# STM32MP25_CM33 register map
File version: 1.3
CPU: CM33 r0p1, little endian, MPU, FPU, vendor SysTick, 8 interrupt priority bits
Registers are 32-bit, read-write, reset 0x0 unless marked. A register's access mark holds for its fields unless they carry their own. Offsets are from the block's base; [hi:lo] are bit positions.

## PKA — PKA register blank and RAM
Base 0x42060000
Same registers: PKA_S 0x52060000
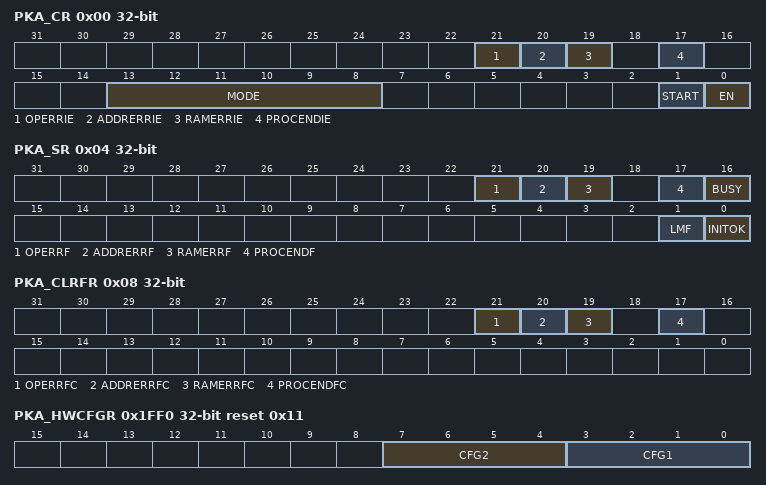
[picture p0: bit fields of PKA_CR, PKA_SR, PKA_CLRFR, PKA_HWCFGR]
0x00 PKA_CR — PKA control register
  [21] OPERRIE — Operation error interrupt enable
    0=No interrupt is generated when OPERRF flag is set in PKA_SR; 1=An interrupt is generated when OPERRF flag is set in PKA_SR
  [20] ADDRERRIE — Address error interrupt enable
    0=No interrupt is generated when ADDRERRF flag is set in PKA_SR; 1=An interrupt is generated when ADDRERRF flag is set in PKA_SR
  [19] RAMERRIE — RAM error interrupt enable
    0=No interrupt is generated when RAMERRF flag is set in PKA_SR; 1=An interrupt is generated when RAMERRF flag is set in PKA_SR
  [17] PROCENDIE — End of operation interrupt enable
    0=No interrupt is generated when PROCENDF flag is set in PKA_SR; 1=An interrupt is generated when PROCENDF flag is set in PKA_SR
  [13:8] MODE — PKA operation code When an operation not listed here is written by the application with EN bit set, OPERRF bit is set in PKA_SR register, and the write to MODE bit field is ignored. When PKA is configured in limited mode (LMF = 1 in PKA_SR), writing a MODE different from 0x26 with EN bit to 1 triggers OPERRF bit to be set and write to MODE bit is ignored.
    0=Montgomery parameter computation then modular exponentiation; 1=Montgomery parameter computation only; 2=Modular exponentiation only (Montgomery parameter must be loaded first); 3=Modular exponentiation (protected, used when manipulating secrets); 32=Montgomery parameter computation then ECC scalar multiplication (protected); 36=ECDSA sign (protected); 38=ECDSA verification; 40=Point on elliptic curve Fp check; 7=RSA CRT exponentiation; 8=Modular inversion; 9=Arithmetic addition; 10=Arithmetic subtraction; 11=Arithmetic multiplication; 12=Arithmetic comparison; 13=Modular reduction; 14=Modular addition; 15=Modular subtraction; 16=Montgomery multiplication; 35=ECC complete addition; 39=ECC double base ladder; 47=ECC projective to affine
  [1] START — start the operation Writing 1 to this bit starts the operation which is selected by MODE[5:0], using the operands and data already written to the PKA RAM. This bit is always read as 0. When an illegal operation is selected while START bit is set no operation is started, and OPERRF bit is set in PKA_SR. Note: START is ignored if PKA is busy.
  [0] EN — PKA enable When an illegal operation is selected while EN = 1, OPERRF bit is set in PKA_SR. See PKA_CR.MODE bit field for details. Note: When EN = 0, PKA RAM can still be accessed by the application.
    0=Disable PKA; 1=Enable PKA. PKA becomes functional when INITOK is set by hardware in PKA_SR.
0x04 PKA_SR ro — PKA status register
  [21] OPERRF — Operation error flag This bit is cleared using OPERRFC bit in PKA_CLRFR.
    0=No event error; 1=An illegal or unknown operation has been selected in PKA_CR register
  [20] ADDRERRF — Address error flag This bit is cleared using ADDRERRFC bit in PKA_CLRFR.
    0=No address error; 1=Address access is out of range (unmapped address)
  [19] RAMERRF — PKA RAM error flag This bit is cleared using RAMERRFC bit in PKA_CLRFR.
    0=No PKA RAM access error; 1=An AHB access to the PKA RAM occurred while the PKA core was computing and using its internal RAM (AHB PKA_RAM access are not allowed while PKA operation is in progress)
  [17] PROCENDF — PKA end of operation flag
    0=Operation in progress; 1=PKA operation is completed. This flag is set when the BUSY bit is deasserted.
  [16] BUSY — Busy flag This bit is set whenever a PKA operation is in progress (START = 1 in PKA_CR). It is automatically cleared when the computation is complete, making PKA RAM accessible again. If PKA is started with a wrong opcode, it stays busy for a couple of cycles, then it aborts automatically the operation and goes back to ready (BUSY = 0).
    0=No operation is in progress (default); 1=An operation is in progress
  [1] LMF — Limited mode flag This bit is updated when EN bit in PKA_CR is set
    0=All values documented in MODE bit field can be used; 1=Only ECDSA verification (MODE = 0x26) is supported by the PKA
  [0] INITOK — PKA initialization OK This bit is asserted when PKA initialization is complete. When RNG is not able to output proper random numbers INITOK stays at 0.
    0=PKA is not initialized correctly. START bit cannot be set.; 1=PKA is initialized correctly and can be used normally
0x08 PKA_CLRFR wo — PKA clear flag register
  [21] OPERRFC — Clear operation error flag
    0=No action; 1=Clear the OPERRF flag in PKA_SR
  [20] ADDRERRFC — Clear address error flag
    0=No action; 1=Clear the ADDRERRF flag in PKA_SR
  [19] RAMERRFC — Clear PKA RAM error flag
    0=No action; 1=Clear the RAMERRF flag in PKA_SR
  [17] PROCENDFC — Clear PKA end of operation flag
    0=No action; 1=Clear the PROCENDF flag in PKA_SR
0x1FF0 PKA_HWCFGR ro reset 0x11 — PKA hardware configuration register
  [7:4] CFG2 — HW Generic 2 This field returns the DPAEN generic value (0x1)
  [3:0] CFG1 — HW Generic 2 This field returns the PKA64_SEL generic value (0x1)
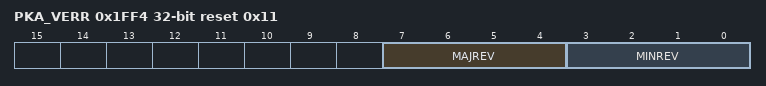
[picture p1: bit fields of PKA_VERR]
0x1FF4 PKA_VERR ro reset 0x11 — PKA version register
  [7:4] MAJREV — Major revision This field returns the PKA major version.
  [3:0] MINREV — Minor revision This field returns the PKA minor version.
0x1FF8 PKA_IPIDR ro reset 0x170072 — PKA identification register
  [31:0] ID — Identification code This field returns the PKA identification code.
0x1FFC PKA_SIDR ro reset 0xA3C5DD08 — PKA size identification register
  [31:0] SID — Size identification code This field returns the size identification code of the PKA as defined below: Bits[31:8] = 0xA3C5DD (fixed code) Bits[7:0] = 0x08 (8KB address decoding)
